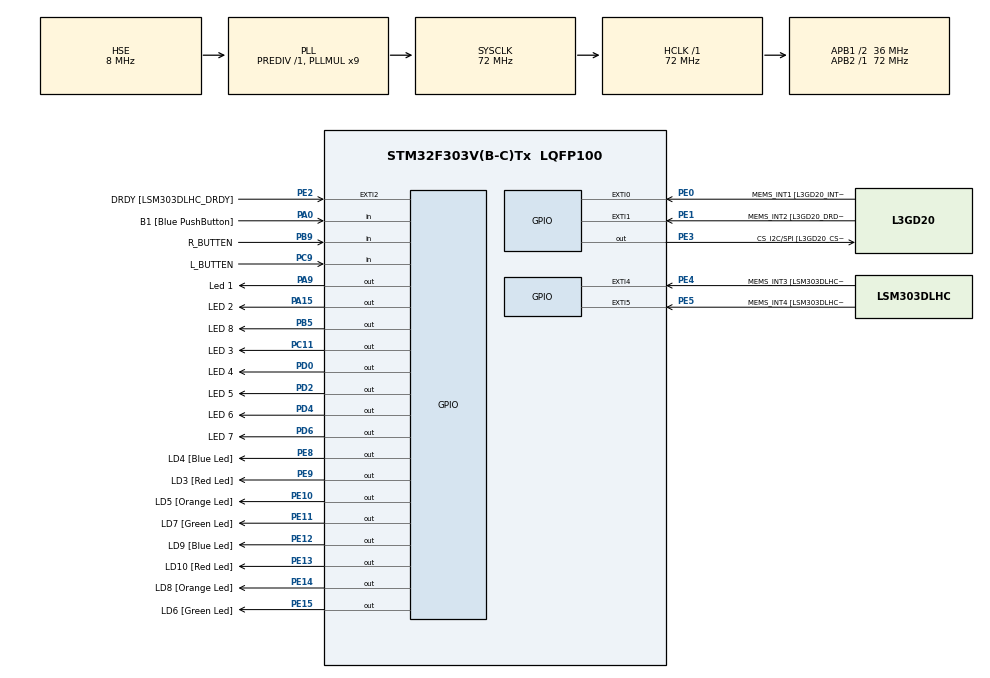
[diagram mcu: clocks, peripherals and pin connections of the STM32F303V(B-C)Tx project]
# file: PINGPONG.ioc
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Mcu.Family=STM32F3
Mcu.Name=STM32F303V(B-C)Tx
Mcu.Package=LQFP100
NVIC.PriorityGroup=NVIC_PRIORITYGROUP_0
PA0.GPIO_Label=B1 [Blue PushButton]
PA0.GPIO_Mode=GPIO_MODE_INPUT
PA0.GPIO_PuPd=GPIO_NOPULL
PA0.Signal=GPIO_Input
PA11.GPIO_Label=DM
PA11.Signal=USB_DM
PA12.GPIO_Label=DP
PA12.Signal=USB_DP
PA13.GPIO_Label=SWDIO
PA13.Signal=SYS_JTMS-SWDIO
PA14.GPIO_Label=SWCLK
PA14.Signal=SYS_JTCK-SWCLK
PA15.GPIO_Label=LED 2
PA15.Signal=GPIO_Output
PA5.GPIO_Label=SPI1_SCK [L3GD20_SCL/SPC]
PA5.GPIO_Mode=GPIO_MODE_AF_PP
PA5.GPIO_PuPd=GPIO_NOPULL
PA5.GPIO_Speed=GPIO_SPEED_FREQ_LOW
PA5.Signal=SPI1_SCK
PA6.GPIO_Label=SPI1_MISO [L3GD20_SA0/SDO]
PA6.GPIO_Mode=GPIO_MODE_AF_PP
PA6.GPIO_PuPd=GPIO_NOPULL
PA6.GPIO_Speed=GPIO_SPEED_FREQ_LOW
PA6.Signal=SPI1_MISO
PA7.GPIO_Label=SPI1_MISO [L3GD20_SDA/SDI/SDO]
PA7.GPIO_Mode=GPIO_MODE_AF_PP
PA7.GPIO_PuPd=GPIO_NOPULL
PA7.GPIO_Speed=GPIO_SPEED_FREQ_LOW
PA7.Signal=SPI1_MOSI
PA9.GPIO_Label=Led 1
PA9.GPIO_ModeDefaultOutputPP=GPIO_MODE_OUTPUT_PP
PA9.Signal=GPIO_Output
PB3.GPIO_Label=SWO
PB3.Signal=SYS_JTDO-TRACESWO
PB5.GPIO_Label=LED 8
PB5.Signal=GPIO_Output
PB6.GPIO_FM6=__NULL
PB6.GPIO_Label=I2C1_SCL [LSM303DLHC_SCL]
PB6.GPIO_Mode=GPIO_MODE_AF_OD
PB6.GPIO_PuPd=GPIO_NOPULL
PB6.GPIO_Speed=GPIO_SPEED_FREQ_LOW
PB6.Signal=I2C1_SCL
PB7.GPIO_FM7=__NULL
PB7.GPIO_Label=I2C1_SDA [LSM303DLHC_SDA]
PB7.GPIO_Mode=GPIO_MODE_AF_OD
PB7.GPIO_PuPd=GPIO_NOPULL
PB7.GPIO_Speed=GPIO_SPEED_FREQ_LOW
PB7.Signal=I2C1_SDA
PB9.GPIO_Label=R_BUTTEN
PB9.GPIO_PuPd=GPIO_NOPULL
PB9.Signal=GPIO_Input
PC11.GPIO_Label=LED 3
PC11.Signal=GPIO_Output
PC14-OSC32_IN.GPIO_Label=OSC32_IN
PC14-OSC32_IN.Signal=RCC_OSC32_IN
PC15-OSC32_OUT.GPIO_Label=OSC32_OUT
PC15-OSC32_OUT.Signal=RCC_OSC32_OUT
PC9.GPIO_Label=L_BUTTEN
PC9.Signal=GPIO_Input
PD0.GPIO_Label=LED 4
PD0.Signal=GPIO_Output
PD2.GPIO_Label=LED 5
PD2.Signal=GPIO_Output
PD4.GPIO_Label=LED 6
PD4.Signal=GPIO_Output
PD6.GPIO_Label=LED 7
PD6.Signal=GPIO_Output
PE0.GPIO_Label=MEMS_INT1 [L3GD20_INT1]
PE0.GPIO_ModeDefaultEXTI=GPIO_MODE_EVT_RISING
PE0.GPIO_PuPd=GPIO_NOPULL
PE0.Signal=GPXTI0
PE1.GPIO_Label=MEMS_INT2 [L3GD20_DRDY/INT2]
PE1.GPIO_ModeDefaultEXTI=GPIO_MODE_EVT_RISING
PE1.GPIO_PuPd=GPIO_NOPULL
PE1.Signal=GPXTI1
PE10.GPIO_Label=LD5 [Orange Led]
PE10.GPIO_ModeDefaultOutputPP=GPIO_MODE_OUTPUT_PP
PE10.GPIO_PuPd=GPIO_NOPULL
PE10.GPIO_Speed=GPIO_SPEED_FREQ_LOW
PE10.Signal=GPIO_Output
PE11.GPIO_Label=LD7 [Green Led]
PE11.GPIO_ModeDefaultOutputPP=GPIO_MODE_OUTPUT_PP
PE11.GPIO_PuPd=GPIO_NOPULL
PE11.GPIO_Speed=GPIO_SPEED_FREQ_LOW
PE11.Signal=GPIO_Output
PE12.GPIO_Label=LD9 [Blue Led]
PE12.GPIO_ModeDefaultOutputPP=GPIO_MODE_OUTPUT_PP
PE12.GPIO_PuPd=GPIO_NOPULL
PE12.GPIO_Speed=GPIO_SPEED_FREQ_LOW
PE12.Signal=GPIO_Output
PE13.GPIO_Label=LD10 [Red Led]
PE13.GPIO_ModeDefaultOutputPP=GPIO_MODE_OUTPUT_PP
PE13.GPIO_PuPd=GPIO_NOPULL
PE13.GPIO_Speed=GPIO_SPEED_FREQ_LOW
PE13.Signal=GPIO_Output
PE14.GPIO_Label=LD8 [Orange Led]
PE14.GPIO_ModeDefaultOutputPP=GPIO_MODE_OUTPUT_PP
PE14.GPIO_PuPd=GPIO_NOPULL
PE14.GPIO_Speed=GPIO_SPEED_FREQ_LOW
PE14.Signal=GPIO_Output
PE15.GPIO_Label=LD6 [Green Led]
PE15.GPIO_ModeDefaultOutputPP=GPIO_MODE_OUTPUT_PP
PE15.GPIO_PuPd=GPIO_NOPULL
PE15.GPIO_Speed=GPIO_SPEED_FREQ_LOW
PE15.Signal=GPIO_Output
PE2.GPIO_Label=DRDY [LSM303DLHC_DRDY]
PE2.GPIO_ModeDefaultEXTI=GPIO_MODE_EVT_RISING
PE2.GPIO_PuPd=GPIO_NOPULL
PE2.Signal=GPXTI2
PE3.GPIO_Label=CS_I2C/SPI [L3GD20_CS_I2C/SPI]
PE3.GPIO_ModeDefaultOutputPP=GPIO_MODE_OUTPUT_PP
PE3.GPIO_PuPd=GPIO_NOPULL
PE3.GPIO_Speed=GPIO_SPEED_FREQ_LOW
PE3.Signal=GPIO_Output
PE4.GPIO_Label=MEMS_INT3 [LSM303DLHC_INT1]
PE4.GPIO_ModeDefaultEXTI=GPIO_MODE_EVT_RISING
PE4.GPIO_PuPd=GPIO_NOPULL
PE4.Signal=GPXTI4
PE5.GPIO_Label=MEMS_INT4 [LSM303DLHC_INT2]
PE5.GPIO_ModeDefaultEXTI=GPIO_MODE_EVT_RISING
PE5.GPIO_PuPd=GPIO_NOPULL
PE5.Signal=GPXTI5
PE8.GPIO_Label=LD4 [Blue Led]
PE8.GPIO_ModeDefaultOutputPP=GPIO_MODE_OUTPUT_PP
PE8.GPIO_PuPd=GPIO_NOPULL
PE8.GPIO_Speed=GPIO_SPEED_FREQ_LOW
PE8.Signal=GPIO_Output
PE9.GPIO_Label=LD3 [Red Led]
PE9.GPIO_ModeDefaultOutputPP=GPIO_MODE_OUTPUT_PP
PE9.GPIO_PuPd=GPIO_NOPULL
PE9.GPIO_Speed=GPIO_SPEED_FREQ_LOW
PE9.Signal=GPIO_Output
PF0-OSC_IN.Mode=HSE-External-Oscillator
PF0-OSC_IN.Signal=RCC_OSC_IN
PF1-OSC_OUT.GPIO_Label=OSC_OUT
PF1-OSC_OUT.Mode=HSE-External-Oscillator
PF1-OSC_OUT.Signal=RCC_OSC_OUT
ProjectManager.HeapSize=0x200
ProjectManager.StackSize=0x400
ProjectManager.TargetToolchain=EWARM
RCC.AHBFreq_Value=72000000
RCC.APB1CLKDivider=RCC_HCLK_DIV2
RCC.APB1Freq_Value=36000000
RCC.APB1TimFreq_Value=72000000
RCC.APB2Freq_Value=72000000
RCC.APB2TimFreq_Value=72000000
RCC.CortexFreq_Value=72000000
RCC.HCLKFreq_Value=72000000
RCC.HSE_VALUE=8000000
RCC.HSIState=RCC_HSI_ON
RCC.HSI_VALUE=8000000
RCC.LSE_VALUE=32768
RCC.PLLMUL=RCC_PLL_MUL9
RCC.PLLSourceVirtual=RCC_PLLSOURCE_HSE
RCC.SYSCLKFreq_VALUE=72000000
RCC.SYSCLKSourceVirtual=RCC_SYSCLKSOURCE_PLLCLK
RCC.USBFreq_Value=72000000
board=STM32F3DISCOVERY

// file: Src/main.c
/**
  ******************************************************************************
  * File Name          : main.c
  * Description        : Main program body
  ******************************************************************************
*/
#include "main.h"
#include "stm32f3xx_hal.h"
#include "gpio.h"
#include "stdbool.h"
#include "stdint.h"

typedef enum{
  Start,
  MoveRight,
  MoveLeft} states;
  states State, NextState;

void SystemClock_Config(void);
void Error_Handler(void);

int main(void)
{
bool ButtenPredded,R_last=false,L_last=false,Lose=false;

uint32_t Varv,Speed,faster_speed=20000;
uint8_t Led;
int Squre_L=0,Squre_R=0;

State = Start;
NextState = State;
Speed = 500000;

  //////////////////////////////////////////////////////////////////////
  HAL_Init();

  /* Configure the system clock */
  SystemClock_Config();

  /* Initialize all configured peripherals */
  MX_GPIO_Init();

 /////////////////////////////////////////////////////////////////////////
  while (1)
  {
  State = NextState;
  printf("Led: %d %d %d\n",Led,Speed,Varv);
  switch(State){
    case Start:

          Led_on(0,0);

        if(Lose == true || Squre_L == 4 || Squre_R==4){
            Blink_LED();
            show_points(Squre_L,Squre_R);

            Lose = false;
            if(Squre_L >= 4 || Squre_R >= 4){
              Squre_L =0;
              Squre_R =0;
              Speed = 500000;
            }

            }

         else if (L_hit() == true && L_last != true)
          {
            Led = 1;
            NextState = MoveRight;
            L_last=true;
            R_last=false;
            while(L_hit() == true);

          }
          else if(R_hit() == true && R_last != true)
          {
            Led=8;
            NextState = MoveLeft;

            L_last=false;
            R_last=true;
            while(R_hit() == true);

           }
          else {
            NextState = Start;
          }

          break;

    case MoveRight:
     Varv = Speed;
      Led_on(Led);

      while(Varv != 0)
      {
        if(R_hit() ){
          ButtenPredded  = true;

        }

        Varv--;
      }
      if(ButtenPredded){
        if(Led == 8){
          Led=7;
         NextState = MoveLeft;
         if((Speed-faster_speed) != 0) Speed -= faster_speed;
               }
        else{
        Squre_L++;
        Lose =true;
        NextState = Start;

        }

    }
    else
    {
      if(Led == 9){
        NextState = Start;
        Squre_L++;
        Lose =true;

      }
       else
         NextState  = MoveRight;
    }
    if(!ButtenPredded) Led++;
       ButtenPredded = false;

      break;

    case MoveLeft:
    {
      Varv = Speed;
      Led_on(Led);

      while(Varv !=0){
        if(L_hit() ){

          ButtenPredded = true;
        }
        Varv--;
      }

      if(ButtenPredded)
      {
            if(Led == 1){
              NextState = MoveRight;
              Led=2;
              if((Speed-faster_speed) != 0) Speed -= faster_speed;

            }
           else{
              NextState = Start;
              Squre_R++;
             Lose =true;
            }
      }
     else{

       if(Led == 0){
            NextState = Start;
            Squre_R++;
            Lose =true;
     }
          else
            NextState = MoveLeft;
        }

        if(!ButtenPredded) Led--;
        ButtenPredded=false;
      }
      break;

    default:
      break;

  }
  /* USER CODE END 3 */

}
}

/** System Clock Configuration
*/
void SystemClock_Config(void)
{

  RCC_OscInitTypeDef RCC_OscInitStruct;
  RCC_ClkInitTypeDef RCC_ClkInitStruct;

    /**Initializes the CPU, AHB and APB busses clocks
    */
  RCC_OscInitStruct.OscillatorType = RCC_OSCILLATORTYPE_HSE;
  RCC_OscInitStruct.HSEState = RCC_HSE_ON;
  RCC_OscInitStruct.HSEPredivValue = RCC_HSE_PREDIV_DIV1;
  RCC_OscInitStruct.HSIState = RCC_HSI_ON;
  RCC_OscInitStruct.PLL.PLLState = RCC_PLL_ON;
  RCC_OscInitStruct.PLL.PLLSource = RCC_PLLSOURCE_HSE;
  RCC_OscInitStruct.PLL.PLLMUL = RCC_PLL_MUL9;
  if (HAL_RCC_OscConfig(&RCC_OscInitStruct) != HAL_OK)
  {
    Error_Handler();
  }

    /**Initializes the CPU, AHB and APB busses clocks
    */
  RCC_ClkInitStruct.ClockType = RCC_CLOCKTYPE_HCLK|RCC_CLOCKTYPE_SYSCLK
                              |RCC_CLOCKTYPE_PCLK1|RCC_CLOCKTYPE_PCLK2;
  RCC_ClkInitStruct.SYSCLKSource = RCC_SYSCLKSOURCE_PLLCLK;
  RCC_ClkInitStruct.AHBCLKDivider = RCC_SYSCLK_DIV1;
  RCC_ClkInitStruct.APB1CLKDivider = RCC_HCLK_DIV2;
  RCC_ClkInitStruct.APB2CLKDivider = RCC_HCLK_DIV1;

  if (HAL_RCC_ClockConfig(&RCC_ClkInitStruct, FLASH_LATENCY_2) != HAL_OK)
  {
    Error_Handler();
  }

    /**Configure the Systick interrupt time
    */
  HAL_SYSTICK_Config(HAL_RCC_GetHCLKFreq()/1000);

    /**Configure the Systick
    */
  HAL_SYSTICK_CLKSourceConfig(SYSTICK_CLKSOURCE_HCLK);

  /* SysTick_IRQn interrupt configuration */
  HAL_NVIC_SetPriority(SysTick_IRQn, 0, 0);
}

void Error_Handler(void)
{
  /* USER CODE BEGIN Error_Handler */
  /* User can add his own implementation to report the HAL error return state */
  while(1)
  {
    HAL_GPIO_WritePin(Led_1_GPIO_Port,Led_1_Pin,GPIO_PIN_SET);// LED 1
    HAL_GPIO_WritePin(Led_1_GPIO_Port,Led_1_Pin,GPIO_PIN_RESET);
  }
  /* USER CODE END Error_Handler */
}

/************************ (C) COPYRIGHT STMicroelectronics *****END OF FILE****/
